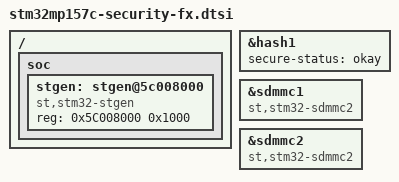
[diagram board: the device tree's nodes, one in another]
/*
 * Copyright (c) 2017-2019, STMicroelectronics - All Rights Reserved
 *
 * SPDX-License-Identifier:	GPL-2.0+	BSD-3-Clause
 */

/ {
	soc {
		stgen: stgen@5c008000 {
			compatible = "st,stm32-stgen";
			reg = <0x5C008000 0x1000>;
			status = "okay";
		};
	};
};

&hash1 {
	secure-status = "okay";
};

&sdmmc1 {
	compatible = "st,stm32-sdmmc2";
};

&sdmmc2 {
	compatible = "st,stm32-sdmmc2";
};
